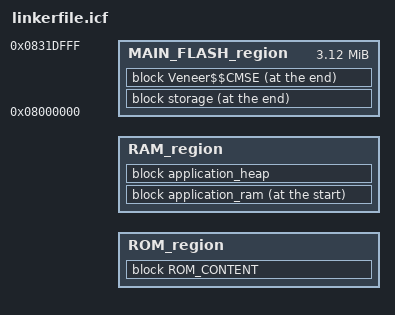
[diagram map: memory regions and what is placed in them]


/*###ICF### Section handled by ICF editor, don't touch! ****/
/*-Editor annotation file-*/
/* IcfEditorFile="$TOOLKIT_DIR$\config\ide\IcfEditor\cortex_v1_0.xml" */
/* Version 4.1.1 */

/*-Memory Regions*/
  define symbol __ICFEDIT_region_ROM_start__ = 0x8000000;
  define symbol __ICFEDIT_region_ROM_end__   = (0x8000000+0x6000-0x40-0x20-1);
  define symbol __ICFEDIT_region_RAM_start__ = 0x20000000;
  define symbol __ICFEDIT_region_RAM_end__   = (0x20000000+0x80000-1);

/**** End of ICF editor section. ###ICF###*/
define memory mem with size = 4G;
define region ROM_region   = mem:[from __ICFEDIT_region_ROM_start__   to __ICFEDIT_region_ROM_end__];
define region RAM_region   = mem:[from __ICFEDIT_region_RAM_start__   to __ICFEDIT_region_RAM_end__];
define region MAIN_FLASH_region   = mem:[from 0x8000000   to (0x8000000+0x31e000-1)];

/* Symbol exported to the application. */
define exported symbol __ram_end__ = (__ICFEDIT_region_RAM_end__ + 1);

/* Symbol used internally by the linker script. */
define symbol STACK_SEAL_SIZE = 8;
define block BOOTLOADER_RESET_REASON with size = 4, alignment = 4
{
  section .reset_reason
};

define block CSTACK with alignment = 8
{
  section .stack
};
define block STACKSEAL with size = STACK_SEAL_SIZE
{
  section .stackseal
};
define block MEMORY_MANAGER_HEAP with expanding size, alignment = 8
{
  section .memory_manager_heap
};

define block Veneer$$CMSE with alignment = 32
{
  section Veneer$$CMSE,
};
keep { block Veneer$$CMSE };

define block storage with alignment = 8192
{
  section INTERNAL_STORAGE,
};
keep { block storage };
define block ROM_CONTENT with fixed order { readonly, readonly section ROM_SIZE};

define block application_ram with fixed order
{
  block BOOTLOADER_RESET_REASON,
  block CSTACK,
  block STACKSEAL,
  readwrite,
};

initialize by copy { readwrite };

define block application_heap with fixed order
{
  block MEMORY_MANAGER_HEAP
};

do not initialize
{
  section .reset_reason,
 section .noinit,
 section .stack,
 section .stackseal,
  section .memory_manager_heap
};

keep { section .intvec };
place in ROM_region   { block ROM_CONTENT };

"storage_regions":
place at end of MAIN_FLASH_region {
  block storage,
  block Veneer$$CMSE
};

"application_ram":
place at start of RAM_region {
  block application_ram,
};

"application_heap":
place in RAM_region {
  block application_heap,
};

